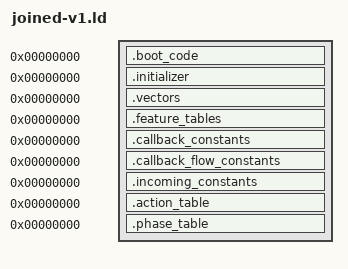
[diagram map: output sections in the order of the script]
OUTPUT_ARCH(riscv)
SECTIONS
{
 .boot_code 0 : SUBALIGN(2) { *(.boot_code)
  *(.text.tsl9_record_dispatch_provider_10d9a)
  *(.text.tsl9_action_primitives_block_10dac)
  *(.text.tsl9_action_primitives_block_10dba)
  *(.text.tsl9_action_primitives_block_10dc8)
  *(.text.tsl9_action_primitives_block_10dca)
  *(.text.tsl9_record_dispatch_provider_1552a)
  *(.text.tsl9_record_dispatch_provider_15532)
  *(.text.tsl9_action_primitives_block_1555a)
  *(.text.tsl9_action_primitives_block_15560)
  *(.text.tsl9_action_primitives_block_15566)
  *(.text.tsl9_action_primitives_block_1556c)
  *(.text.tsl9_action_primitives_block_15570)
  *(.text.tsl9_action_primitives_block_1557e)
  *(.text.tsl9_action_primitives_block_15582)
  *(.text.tsl9_action_primitives_provider_17f80)
  *(.text.tsl9_action_primitives_block_17f8a)
  *(.text.tsl9_action_primitives_block_17f94)
  *(.text.tsl9_action_primitives_block_17fa8)
  *(.text.tsl9_action_primitives_block_17fc4)
  *(.text.tsl9_action_primitives_block_17fd8)
  *(.text.tsl9_action_primitives_block_17fde)
  *(.text.tsl9_action_primitives_block_17ff4)
  *(.text.tsl9_action_primitives_block_17ff8)
  *(.text.tsl9_action_primitives_block_17ffe)
  *(.text.tsl9_action_primitives_block_1800c)
  *(.text.tsl9_action_primitives_block_1800e)
  *(.text.tsl9_action_primitives_block_1802c)
  *(.text.tsl9_registered_callbacks_provider_1802e)
  *(.text.tsl9_action_primitives_block_18040)
  *(.text.tsl9_action_primitives_block_1804c)
  *(.text.tsl9_action_primitives_provider_1805a)
  *(.text.tsl9_action_primitives_block_18076)
  *(.text.tsl9_action_primitives_block_18090)
  *(.text.tsl9_action_primitives_block_18092)
  *(.text.tsl9_action_primitives_block_18096)
  *(.text.tsl9_action_primitives_block_18098)
  *(.text.tsl9_action_primitives_block_1809c)
  *(.text.tsl9_action_primitives_block_1809e)
  *(.text.tsl9_action_primitives_block_180a8)
  *(.text.tsl9_action_primitives_block_180c6)
  *(.text.tsl9_action_primitives_block_180c8)
  *(.text.tsl9_action_primitives_block_180cc)
  *(.text.tsl9_action_primitives_block_180ce)
  *(.text.tsl9_action_primitives_block_180d4)
  *(.text.tsl9_action_primitives_block_180d6)
  *(.text.tsl9_action_primitives_block_180da)
  *(.text.tsl9_action_primitives_block_180dc)
  *(.text.tsl9_action_primitives_block_180e2)
  *(.text.tsl9_action_primitives_block_180e4)
  *(.text.tsl9_action_primitives_block_180e8)
  *(.text.tsl9_action_primitives_block_180ea)
  *(.text.tsl9_action_primitives_provider_180f0)
  *(.text.tsl9_action_primitives_block_180fe)
  *(.text.tsl9_registered_callbacks_provider_18110)
  *(.text.tsl9_record_dispatch_provider_1811a)
  *(.text.tsl9_action_primitives_block_18144)
  *(.text.tsl9_action_primitives_block_18146)
  *(.text.tsl9_action_primitives_block_1814a)
  *(.text.tsl9_action_primitives_block_18154)
  *(.text.tsl9_action_primitives_block_1815a)
  *(.text.tsl9_action_primitives_block_18170)
  *(.text.tsl9_action_primitives_block_18172)
  *(.text.tsl9_action_primitives_block_1817e)
  *(.text.tsl9_action_primitives_block_18180)
  *(.text.tsl9_action_primitives_block_18186)
  *(.text.tsl9_action_primitives_block_18192)
  *(.text.tsl9_action_primitives_block_18196)
  *(.text.tsl9_action_primitives_block_18198)
 }
 .initializer 0 : SUBALIGN(4) { *(.initializer) }
 .vectors 0 : SUBALIGN(4) { *(.vectors) }
 .feature_tables 0 : SUBALIGN(4) { *(.feature_tables) }
 .callback_constants 0 : SUBALIGN(4) { *(.callback_constants) }
 .callback_flow_constants 0 : SUBALIGN(4) { *(.callback_flow_constants) }
 .incoming_constants 0 : SUBALIGN(4) { *(.incoming_constants) }
 .action_table 0 : SUBALIGN(4) { *(.action_table) }
 .phase_table 0 : SUBALIGN(4) { *(.rodata.tsl9_action_primitives_table_1ab04) }
 /DISCARD/ : { *(.comment) *(.riscv.attributes) *(.llvm_addrsig) }
}
